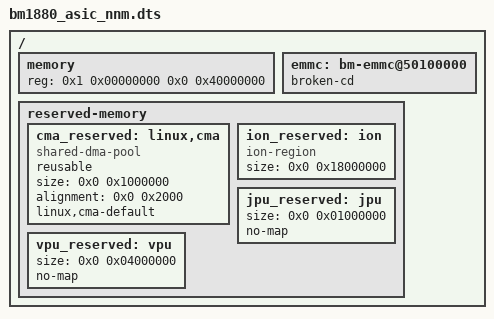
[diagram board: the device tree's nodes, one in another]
/dts-v1/;

#include "bm1880_asic.dtsi"

/ {
	memory {
		reg = <0x1 0x00000000 0x0 0x40000000>; // 1GB
		device_type = "memory";
	};

	emmc:bm-emmc@50100000 {
		broken-cd;
	};

	reserved-memory {
		#address-cells = <0x2>;
		#size-cells = <0x2>;
		ranges;

		cma_reserved: linux,cma {
			compatible = "shared-dma-pool";
			reusable;
			size = <0x0 0x1000000>; // 16MB
			alignment = <0x0 0x2000>; // 8KB
			linux,cma-default;
		};

		ion_reserved: ion {
			compatible = "ion-region";
			size = <0x0 0x18000000>; // 384MB
		};

		jpu_reserved: jpu {
			size = <0x0 0x01000000>; // 16M
			no-map;
		};

		vpu_reserved: vpu {
			size = <0x0 0x04000000>; // 64M
			no-map;
		};
	};
	/delete-node/ ethernet@58008000;
	/delete-node/ ethernet@58028000;
	/delete-node/ aliases;
};
